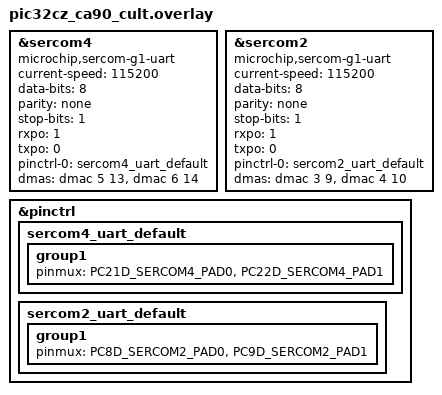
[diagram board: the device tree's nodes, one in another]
/*
 * SPDX-FileCopyrightText: Copyright (c) 2026 Microchip Technology Inc.
 *
 * SPDX-License-Identifier: Apache-2.0
 */

/* connect the PC21 to PC9 and PC22 to PC8 */

dut: &sercom4 {
	compatible = "microchip,sercom-g1-uart";
	#address-cells = <1>;
	#size-cells = <0>;

	current-speed = <115200>;
	data-bits = <8>;
	parity = "none";
	stop-bits = "1";

	rxpo = <1>;
	txpo = <0>;

	pinctrl-0 = <&sercom4_uart_default>;
	pinctrl-names = "default";

	dmas = <&dmac 5 13>, <&dmac 6 14>;
	dma-names = "rx", "tx";
	status = "okay";
};

dut_aux: &sercom2 {
	compatible = "microchip,sercom-g1-uart";
	/delete-property/ dipo;
	/delete-property/ dopo;
	/delete-property/ cs-gpios;
	#address-cells = <1>;
	#size-cells = <0>;

	current-speed = <115200>;
	data-bits = <8>;
	parity = "none";
	stop-bits = "1";

	rxpo = <1>;
	txpo = <0>;

	pinctrl-0 = <&sercom2_uart_default>;
	pinctrl-names = "default";

	dmas = <&dmac 3 9>, <&dmac 4 10>;
	dma-names = "rx", "tx";
	status = "okay";
};

&pinctrl {
	sercom4_uart_default: sercom4_uart_default {
		group1 {
			pinmux = <PC21D_SERCOM4_PAD0>,
				 <PC22D_SERCOM4_PAD1>;
		};
	};

	sercom2_uart_default: sercom2_uart_default {
		group1 {
			pinmux = <PC8D_SERCOM2_PAD0>,
				 <PC9D_SERCOM2_PAD1>;
		};
	};
};
